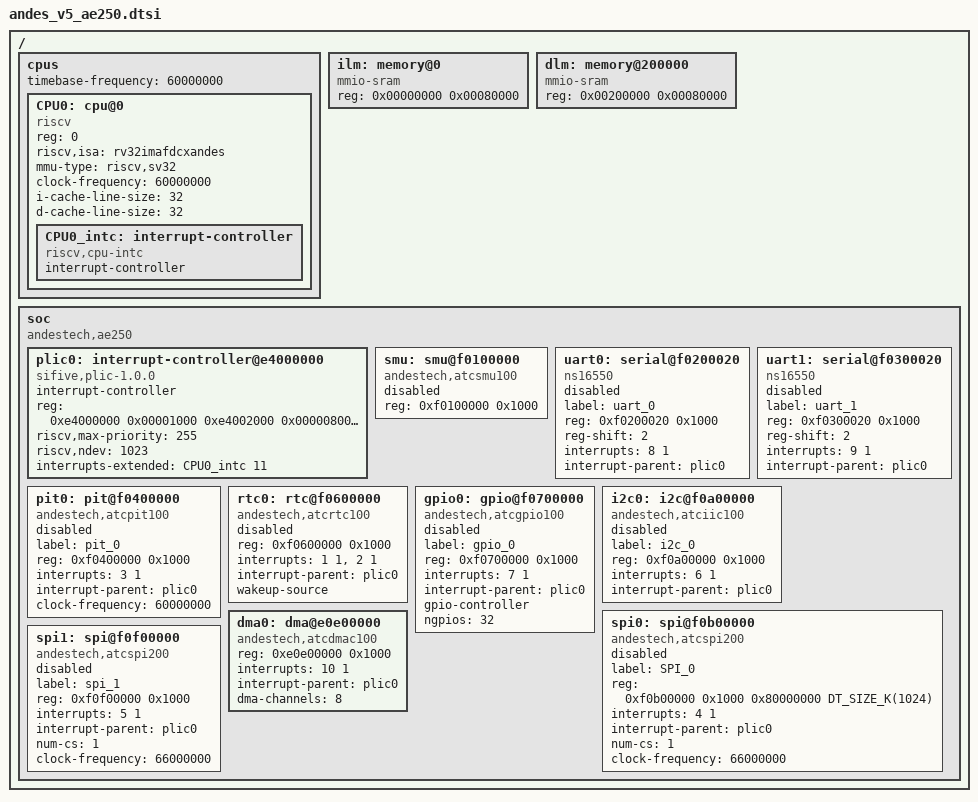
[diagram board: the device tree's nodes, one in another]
/*
 * Copyright (c) 2021 Andes Technology Corporation
 *
 * SPDX-License-Identifier: Apache-2.0
 */

/dts-v1/;
#include <dt-bindings/gpio/gpio.h>
#include <mem.h>

/ {
	#address-cells = <1>;
	#size-cells = <1>;

	cpus {
		#address-cells = <1>;
		#size-cells = <0>;
		timebase-frequency = <60000000>;
		CPU0: cpu@0 {
			compatible = "riscv";
			device_type = "cpu";
			reg = <0>;
			status = "okay";
			riscv,isa = "rv32imafdcxandes";
			mmu-type = "riscv,sv32";
			clock-frequency = <60000000>;
			i-cache-line-size = <32>;
			d-cache-line-size = <32>;
			CPU0_intc: interrupt-controller {
				#address-cells = <0>;
				#interrupt-cells = <1>;
				interrupt-controller;
				compatible = "riscv,cpu-intc";
			};
		};
	};

	ilm: memory@0 {
		device_type = "memory";
		compatible = "mmio-sram";
		reg = <0x00000000 0x00080000>;
	};

	dlm: memory@200000 {
		device_type = "memory";
		compatible = "mmio-sram";
		reg = <0x00200000 0x00080000>;
	};

	soc {
		#address-cells = <1>;
		#size-cells = <1>;
		compatible = "andestech,ae250";
		ranges;

		plic0: interrupt-controller@e4000000 {
			compatible = "sifive,plic-1.0.0";
			#address-cells = <1>;
			#interrupt-cells = <2>;
			interrupt-controller;
			reg = <	0xe4000000 0x00001000
				0xe4002000 0x00000800
				0xe4200000 0x00010000 >;
			reg-names = "prio", "irq_en", "reg";
			riscv,max-priority = <255>;
			riscv,ndev = <1023>;
			interrupts-extended = <&CPU0_intc 11>;
		};

		smu: smu@f0100000 {
			compatible = "andestech,atcsmu100";
			reg = <0xf0100000 0x1000>;
			status = "disabled";
		};

		uart0: serial@f0200020 {
			compatible = "ns16550";
			label = "uart_0";
			reg = <0xf0200020 0x1000>;
			reg-shift = <2>;
			interrupts = <8 1>;
			interrupt-parent = <&plic0>;
			status = "disabled";
		};

		uart1: serial@f0300020 {
			compatible = "ns16550";
			label = "uart_1";
			reg = <0xf0300020 0x1000>;
			reg-shift = <2>;
			interrupts = <9 1>;
			interrupt-parent = <&plic0>;
			status = "disabled";
		};

		pit0: pit@f0400000 {
			compatible = "andestech,atcpit100";
			label = "pit_0";
			reg = <0xf0400000 0x1000>;
			interrupts = <3 1>;
			interrupt-parent = <&plic0>;
			clock-frequency = <60000000>;
			status = "disabled";
		};

		rtc0: rtc@f0600000 {
			compatible = "andestech,atcrtc100";
			reg = <0xf0600000 0x1000>;
			interrupts = <1 1>, <2 1>;
			interrupt-parent = <&plic0>;
			wakeup-source;
			status = "disabled";
		};

		gpio0: gpio@f0700000 {
			compatible = "andestech,atcgpio100";
			label = "gpio_0";
			reg = <0xf0700000 0x1000>;
			interrupts = <7 1>;
			interrupt-parent = <&plic0>;
			gpio-controller;
			ngpios = <32>;
			#gpio-cells = <2>;
			status = "disabled";
		};

		i2c0: i2c@f0a00000 {
			compatible = "andestech,atciic100";
			label = "i2c_0";
			reg = <0xf0a00000 0x1000>;
			interrupts = <6 1>;
			interrupt-parent = <&plic0>;
			#address-cells = <1>;
			#size-cells = <0>;
			status = "disabled";
		};

		spi0: spi@f0b00000 {
			compatible = "andestech,atcspi200";
			label = "SPI_0";
			reg = <0xf0b00000 0x1000
			       0x80000000 DT_SIZE_K(1024)>;
			reg-names = "control", "mem";
			interrupts = <4 1>;
			interrupt-parent = <&plic0>;
			#address-cells = <1>;
			#size-cells = <0>;
			num-cs = <1>;
			clock-frequency = <66000000>;
			status = "disabled";
		};

		spi1: spi@f0f00000 {
			compatible = "andestech,atcspi200";
			label = "spi_1";
			reg = <0xf0f00000 0x1000>;
			reg-names = "control";
			interrupts = <5 1>;
			interrupt-parent = <&plic0>;
			#address-cells = <1>;
			#size-cells = <0>;
			num-cs = <1>;
			clock-frequency = <66000000>;
			status = "disabled";
		};

		dma0: dma@e0e00000 {
			compatible = "andestech,atcdmac100";
			reg = <0xe0e00000 0x1000>;
			interrupts = <10 1>;
			interrupt-parent = <&plic0>;
			dma-channels = <8>;
		};
	};
};
